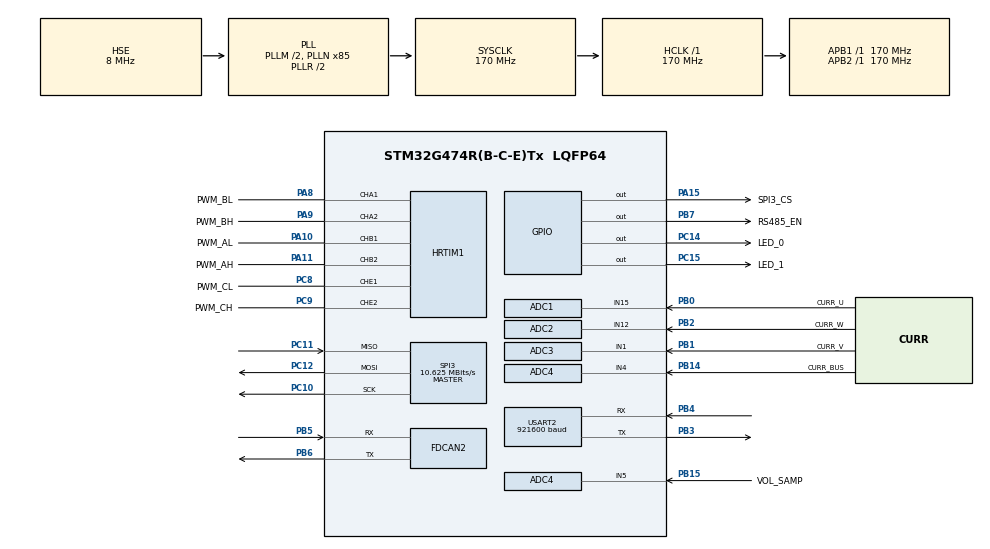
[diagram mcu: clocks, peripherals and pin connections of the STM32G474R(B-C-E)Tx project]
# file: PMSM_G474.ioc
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ADC1.Channel-5\#ChannelRegularConversion=ADC_CHANNEL_15
ADC1.DMAContinuousRequests=ENABLE
ADC1.EOCSelection=ADC_EOC_SEQ_CONV
ADC1.ExternalTrigConv=ADC_EXTERNALTRIG_HRTIM_TRG1
ADC1.NbrOfConversion=1
ADC1.NbrOfConversionFlag=1
ADC1.OffsetNumber-5\#ChannelRegularConversion=ADC_OFFSET_NONE
ADC1.Rank-5\#ChannelRegularConversion=1
ADC1.SamplingTime-5\#ChannelRegularConversion=ADC_SAMPLETIME_47CYCLES_5
ADC1.master=1
ADC2.Channel-4\#ChannelRegularConversion=ADC_CHANNEL_12
ADC2.DMAContinuousRequests=ENABLE
ADC2.ExternalTrigConv=ADC_EXTERNALTRIG_HRTIM_TRG1
ADC2.NbrOfConversionFlag=1
ADC2.OffsetNumber-4\#ChannelRegularConversion=ADC_OFFSET_NONE
ADC2.Rank-4\#ChannelRegularConversion=1
ADC2.SamplingTime-4\#ChannelRegularConversion=ADC_SAMPLETIME_47CYCLES_5
ADC3.Channel-3\#ChannelRegularConversion=ADC_CHANNEL_1
ADC3.DMAContinuousRequests=ENABLE
ADC3.ExternalTrigConv=ADC_EXTERNALTRIG_HRTIM_TRG2
ADC3.NbrOfConversionFlag=1
ADC3.OffsetNumber-3\#ChannelRegularConversion=ADC_OFFSET_NONE
ADC3.Rank-3\#ChannelRegularConversion=1
ADC3.SamplingTime-3\#ChannelRegularConversion=ADC_SAMPLETIME_47CYCLES_5
ADC3.master=1
ADC4.Channel-3\#ChannelRegularConversion=ADC_CHANNEL_5
ADC4.Channel-4\#ChannelRegularConversion=ADC_CHANNEL_4
ADC4.DMAContinuousRequests=ENABLE
ADC4.EOCSelection=ADC_EOC_SEQ_CONV
ADC4.ExternalTrigConv=ADC_EXTERNALTRIG_HRTIM_TRG2
ADC4.NbrOfConversion=2
ADC4.NbrOfConversionFlag=1
ADC4.OffsetNumber-3\#ChannelRegularConversion=ADC_OFFSET_NONE
ADC4.OffsetNumber-4\#ChannelRegularConversion=ADC_OFFSET_NONE
ADC4.Rank-3\#ChannelRegularConversion=1
ADC4.Rank-4\#ChannelRegularConversion=2
ADC4.SamplingTime-3\#ChannelRegularConversion=ADC_SAMPLETIME_47CYCLES_5
ADC4.SamplingTime-4\#ChannelRegularConversion=ADC_SAMPLETIME_47CYCLES_5
Dma.ADC1.2.Direction=DMA_PERIPH_TO_MEMORY
Dma.ADC1.2.EventEnable=DISABLE
Dma.ADC1.2.Instance=DMA1_Channel1
Dma.ADC1.2.MemDataAlignment=DMA_MDATAALIGN_HALFWORD
Dma.ADC1.2.MemInc=DMA_MINC_ENABLE
Dma.ADC1.2.Mode=DMA_CIRCULAR
Dma.ADC1.2.PeriphDataAlignment=DMA_PDATAALIGN_HALFWORD
Dma.ADC1.2.PeriphInc=DMA_PINC_DISABLE
Dma.ADC1.2.Polarity=HAL_DMAMUX_REQ_GEN_RISING
Dma.ADC1.2.Priority=DMA_PRIORITY_LOW
Dma.ADC1.2.RequestNumber=1
Dma.ADC1.2.SignalID=NONE
Dma.ADC1.2.SyncEnable=DISABLE
Dma.ADC1.2.SyncPolarity=HAL_DMAMUX_SYNC_NO_EVENT
Dma.ADC1.2.SyncRequestNumber=1
Dma.ADC1.2.SyncSignalID=NONE
Dma.ADC2.4.Direction=DMA_PERIPH_TO_MEMORY
Dma.ADC2.4.EventEnable=DISABLE
Dma.ADC2.4.Instance=DMA1_Channel5
Dma.ADC2.4.MemDataAlignment=DMA_MDATAALIGN_HALFWORD
Dma.ADC2.4.MemInc=DMA_MINC_ENABLE
Dma.ADC2.4.Mode=DMA_CIRCULAR
Dma.ADC2.4.PeriphDataAlignment=DMA_PDATAALIGN_HALFWORD
Dma.ADC2.4.PeriphInc=DMA_PINC_DISABLE
Dma.ADC2.4.Polarity=HAL_DMAMUX_REQ_GEN_RISING
Dma.ADC2.4.Priority=DMA_PRIORITY_LOW
Dma.ADC2.4.RequestNumber=1
Dma.ADC2.4.SignalID=NONE
Dma.ADC2.4.SyncEnable=DISABLE
Dma.ADC2.4.SyncPolarity=HAL_DMAMUX_SYNC_NO_EVENT
Dma.ADC2.4.SyncRequestNumber=1
Dma.ADC2.4.SyncSignalID=NONE
Dma.ADC3.3.Direction=DMA_PERIPH_TO_MEMORY
Dma.ADC3.3.EventEnable=DISABLE
Dma.ADC3.3.Instance=DMA1_Channel4
Dma.ADC3.3.MemDataAlignment=DMA_MDATAALIGN_HALFWORD
Dma.ADC3.3.MemInc=DMA_MINC_ENABLE
Dma.ADC3.3.Mode=DMA_CIRCULAR
Dma.ADC3.3.PeriphDataAlignment=DMA_PDATAALIGN_HALFWORD
Dma.ADC3.3.PeriphInc=DMA_PINC_DISABLE
Dma.ADC3.3.Polarity=HAL_DMAMUX_REQ_GEN_RISING
Dma.ADC3.3.Priority=DMA_PRIORITY_LOW
Dma.ADC3.3.RequestNumber=1
Dma.ADC3.3.SignalID=NONE
Dma.ADC3.3.SyncEnable=DISABLE
Dma.ADC3.3.SyncPolarity=HAL_DMAMUX_SYNC_NO_EVENT
Dma.ADC3.3.SyncRequestNumber=1
Dma.ADC3.3.SyncSignalID=NONE
Dma.ADC4.5.Direction=DMA_PERIPH_TO_MEMORY
Dma.ADC4.5.EventEnable=DISABLE
Dma.ADC4.5.Instance=DMA1_Channel6
Dma.ADC4.5.MemDataAlignment=DMA_MDATAALIGN_HALFWORD
Dma.ADC4.5.MemInc=DMA_MINC_ENABLE
Dma.ADC4.5.Mode=DMA_CIRCULAR
Dma.ADC4.5.PeriphDataAlignment=DMA_PDATAALIGN_HALFWORD
Dma.ADC4.5.PeriphInc=DMA_PINC_DISABLE
Dma.ADC4.5.Polarity=HAL_DMAMUX_REQ_GEN_RISING
Dma.ADC4.5.Priority=DMA_PRIORITY_LOW
Dma.ADC4.5.RequestNumber=1
Dma.ADC4.5.SignalID=NONE
Dma.ADC4.5.SyncEnable=DISABLE
Dma.ADC4.5.SyncPolarity=HAL_DMAMUX_SYNC_NO_EVENT
Dma.ADC4.5.SyncRequestNumber=1
Dma.ADC4.5.SyncSignalID=NONE
Dma.Request0=USART2_TX
Dma.Request1=SPI3_RX
Dma.Request2=ADC1
Dma.Request3=ADC3
Dma.Request4=ADC2
Dma.Request5=ADC4
Dma.Request6=SPI3_TX
Dma.SPI3_RX.1.Direction=DMA_PERIPH_TO_MEMORY
Dma.SPI3_RX.1.EventEnable=DISABLE
Dma.SPI3_RX.1.Instance=DMA1_Channel3
Dma.SPI3_RX.1.MemDataAlignment=DMA_MDATAALIGN_BYTE
Dma.SPI3_RX.1.MemInc=DMA_MINC_ENABLE
Dma.SPI3_RX.1.Mode=DMA_NORMAL
Dma.SPI3_RX.1.PeriphDataAlignment=DMA_PDATAALIGN_BYTE
Dma.SPI3_RX.1.PeriphInc=DMA_PINC_DISABLE
Dma.SPI3_RX.1.Polarity=HAL_DMAMUX_REQ_GEN_RISING
Dma.SPI3_RX.1.Priority=DMA_PRIORITY_LOW
Dma.SPI3_RX.1.RequestNumber=1
Dma.SPI3_RX.1.SignalID=NONE
Dma.SPI3_RX.1.SyncEnable=DISABLE
Dma.SPI3_RX.1.SyncPolarity=HAL_DMAMUX_SYNC_NO_EVENT
Dma.SPI3_RX.1.SyncRequestNumber=1
Dma.SPI3_RX.1.SyncSignalID=NONE
Dma.SPI3_TX.6.Direction=DMA_MEMORY_TO_PERIPH
Dma.SPI3_TX.6.EventEnable=DISABLE
Dma.SPI3_TX.6.Instance=DMA1_Channel7
Dma.SPI3_TX.6.MemDataAlignment=DMA_MDATAALIGN_BYTE
Dma.SPI3_TX.6.MemInc=DMA_MINC_ENABLE
Dma.SPI3_TX.6.Mode=DMA_NORMAL
Dma.SPI3_TX.6.PeriphDataAlignment=DMA_PDATAALIGN_BYTE
Dma.SPI3_TX.6.PeriphInc=DMA_PINC_DISABLE
Dma.SPI3_TX.6.Polarity=HAL_DMAMUX_REQ_GEN_RISING
Dma.SPI3_TX.6.Priority=DMA_PRIORITY_LOW
Dma.SPI3_TX.6.RequestNumber=1
Dma.SPI3_TX.6.SignalID=NONE
Dma.SPI3_TX.6.SyncEnable=DISABLE
Dma.SPI3_TX.6.SyncPolarity=HAL_DMAMUX_SYNC_NO_EVENT
Dma.SPI3_TX.6.SyncRequestNumber=1
Dma.SPI3_TX.6.SyncSignalID=NONE
Dma.USART2_TX.0.Direction=DMA_MEMORY_TO_PERIPH
Dma.USART2_TX.0.EventEnable=DISABLE
Dma.USART2_TX.0.Instance=DMA1_Channel2
Dma.USART2_TX.0.MemDataAlignment=DMA_MDATAALIGN_BYTE
Dma.USART2_TX.0.MemInc=DMA_MINC_ENABLE
Dma.USART2_TX.0.Mode=DMA_NORMAL
Dma.USART2_TX.0.PeriphDataAlignment=DMA_PDATAALIGN_BYTE
Dma.USART2_TX.0.PeriphInc=DMA_PINC_DISABLE
Dma.USART2_TX.0.Polarity=HAL_DMAMUX_REQ_GEN_RISING
Dma.USART2_TX.0.Priority=DMA_PRIORITY_LOW
Dma.USART2_TX.0.RequestNumber=1
Dma.USART2_TX.0.SignalID=NONE
Dma.USART2_TX.0.SyncEnable=DISABLE
Dma.USART2_TX.0.SyncPolarity=HAL_DMAMUX_SYNC_NO_EVENT
Dma.USART2_TX.0.SyncRequestNumber=1
Dma.USART2_TX.0.SyncSignalID=NONE
FDCAN2.CalculateBaudRateNominal=999999
FDCAN2.CalculateTimeBitNominal=1000
FDCAN2.CalculateTimeQuantumNominal=58.82352941176471
FDCAN2.DataPrescaler=17
FDCAN2.DataSyncJumpWidth=9
FDCAN2.DataTimeSeg1=5
FDCAN2.DataTimeSeg2=4
FDCAN2.NominalPrescaler=10
FDCAN2.NominalSyncJumpWidth=9
FDCAN2.NominalTimeSeg1=8
FDCAN2.NominalTimeSeg2=8
FDCAN2.StdFiltersNbr=1
HRTIM1.ADCTrigger1_Source1=HRTIM_ADCTRIGGEREVENT13_MASTER_CMP1
HRTIM1.ADCTrigger2_Source1=HRTIM_ADCTRIGGEREVENT24_MASTER_CMP1
HRTIM1.ADCTrigger4_Source1=HRTIM_ADCTRIGGEREVENT24_MASTER_PERIOD
HRTIM1.ADCTrigger_Id1=HRTIM_ADCTRIGGER_1
HRTIM1.ADCTrigger_Id2=HRTIM_ADCTRIGGER_2
HRTIM1.ADCTrigger_Id4=HRTIM_ADCTRIGGER_4
HRTIM1.CompareUnit1-MasterTimer=HRTIM_COMPAREUNIT_1
HRTIM1.CompareUnit1-Output_TA1TA2=HRTIM_COMPAREUNIT_1
HRTIM1.CompareUnit1-Output_TB1TB2=HRTIM_COMPAREUNIT_1
HRTIM1.CompareUnit1-Output_TE1TE2=HRTIM_COMPAREUNIT_1
HRTIM1.CompareValue1-MasterTimer=ADC_TRIG
HRTIM1.CompareValue1-Output_TA1TA2=0xFFFB
HRTIM1.DeadTimeInsertion-Output_TA1TA2=HRTIM_TIMDEADTIMEINSERTION_ENABLED
HRTIM1.DeadTimeInsertion-Output_TB1TB2=HRTIM_TIMDEADTIMEINSERTION_ENABLED
HRTIM1.DeadTimeInsertion-Output_TE1TE2=HRTIM_TIMDEADTIMEINSERTION_ENABLED
HRTIM1.Deadtimeconfig-Output_TB1TB2=HRTIM_TIMERINDEX_TIMER_B
HRTIM1.FallingValue-Output_TA1TA2=0x032
HRTIM1.FallingValue-Output_TB1TB2=0x032
HRTIM1.FallingValue-Output_TE1TE2=0x032
HRTIM1.GreaterCMP1_TA=HRTIM_TIMERGTCMP1_GREATER
HRTIM1.GreaterCMP1_TB=HRTIM_TIMERGTCMP1_GREATER
HRTIM1.GreaterCMP1_TE=HRTIM_TIMERGTCMP1_GREATER
HRTIM1.InterleavedMode-MasterTimer=HRTIM_INTERLEAVED_MODE_DISABLED
HRTIM1.InterruptRequests1_Master=HRTIM_MASTER_IT_MREP
HRTIM1.InterruptRequests2_Master=HRTIM_MASTER_IT_MUPD
HRTIM1.ModeTimeBase-Output_TA1TA2=HRTIM_MODE_CONTINUOUS
HRTIM1.ModeTimeBase-Output_TB1TB2=HRTIM_MODE_CONTINUOUS
HRTIM1.NumberADCTriggerSource1=1
HRTIM1.NumberADCTriggerSource2=1
HRTIM1.NumberADCTriggerSource4=1
HRTIM1.NumberInterruptRequests-Output_TE1TE2=0
HRTIM1.NumberInterruptRequests_Master-MasterTimer=2
HRTIM1.NumberResetSource1-Output_TA1TA2=0
HRTIM1.NumberResetSource1-Output_TB1TB2=0
HRTIM1.NumberResetSource1-Output_TE1TE2=0
HRTIM1.NumberResetTrigger-Output_TA1TA2=0
HRTIM1.NumberResetTrigger-Output_TB1TB2=0
HRTIM1.NumberResetTrigger-Output_TE1TE2=0
HRTIM1.NumberSetSource1-Output_TA1TA2=1
HRTIM1.NumberSetSource1-Output_TB1TB2=1
HRTIM1.NumberSetSource1-Output_TE1TE2=1
HRTIM1.NumberUpdateTrigger-Output_TA1TA2=1
HRTIM1.NumberUpdateTrigger-Output_TB1TB2=1
HRTIM1.NumberUpdateTrigger-Output_TE1TE2=1
HRTIM1.Periode_MASTER=MASTER_ARR
HRTIM1.Periode_TA=HRTIMR_ARR
HRTIM1.Periode_TB=HRTIMR_ARR
HRTIM1.Periode_TE=HRTIMR_ARR
HRTIM1.PreloadEnable-MasterTimer=HRTIM_PRELOAD_ENABLED
HRTIM1.PreloadEnable-Output_TA1TA2=HRTIM_PRELOAD_ENABLED
HRTIM1.PreloadEnable-Output_TB1TB2=HRTIM_PRELOAD_ENABLED
HRTIM1.PreloadEnable-Output_TE1TE2=HRTIM_PRELOAD_ENABLED
HRTIM1.PrescalerDead-Output_TA1TA2=HRTIM_TIMDEADTIME_PRESCALERRATIO_DIV1
HRTIM1.PrescalerDead-Output_TB1TB2=HRTIM_TIMDEADTIME_PRESCALERRATIO_DIV1
HRTIM1.PrescalerDead-Output_TE1TE2=HRTIM_TIMDEADTIME_PRESCALERRATIO_DIV1
HRTIM1.PrescalerRatio_MASTER=HRTIM_PRESCALERRATIO_MUL4
HRTIM1.PrescalerRatio_TA=HRTIM_PRESCALERRATIO_MUL4
HRTIM1.PrescalerRatio_TB=HRTIM_PRESCALERRATIO_MUL4
HRTIM1.PrescalerRatio_TE=HRTIM_PRESCALERRATIO_MUL4
HRTIM1.PushPull-Output_TA1TA2=HRTIM_TIMPUSHPULLMODE_DISABLED
HRTIM1.PushPull-Output_TB1TB2=HRTIM_TIMPUSHPULLMODE_DISABLED
HRTIM1.PushPull-Output_TE1TE2=HRTIM_TIMPUSHPULLMODE_DISABLED
HRTIM1.RepetitionUpdate-MasterTimer=HRTIM_UPDATEONREPETITION_ENABLED
HRTIM1.RepetitionUpdate-Output_TA1TA2=HRTIM_UPDATEONREPETITION_ENABLED
HRTIM1.RepetitionUpdate-Output_TB1TB2=HRTIM_UPDATEONREPETITION_ENABLED
HRTIM1.RepetitionUpdate-Output_TE1TE2=HRTIM_UPDATEONREPETITION_ENABLED
HRTIM1.RisingValue-Output_TA1TA2=0x032
HRTIM1.RisingValue-Output_TB1TB2=0x032
HRTIM1.RisingValue-Output_TE1TE2=0x032
HRTIM1.SetOutput1_Source1-Output_TA1TA2=HRTIM_OUTPUTSET_TIMCMP1
HRTIM1.SetOutput1_Source1-Output_TB1TB2=HRTIM_OUTPUTSET_TIMCMP1
HRTIM1.SetOutput1_Source1-Output_TE1TE2=HRTIM_OUTPUTSET_TIMCMP1
HRTIM1.UpDownMode-Output_TA1TA2=HRTIM_TIMERUPDOWNMODE_UPDOWN
HRTIM1.UpDownMode-Output_TB1TB2=HRTIM_TIMERUPDOWNMODE_UPDOWN
HRTIM1.UpDownMode-Output_TE1TE2=HRTIM_TIMERUPDOWNMODE_UPDOWN
HRTIM1.UpdateTrigger1-Output_TA1TA2=HRTIM_TIMUPDATETRIGGER_MASTER
HRTIM1.UpdateTrigger1-Output_TB1TB2=HRTIM_TIMUPDATETRIGGER_MASTER
HRTIM1.UpdateTrigger1-Output_TE1TE2=HRTIM_TIMUPDATETRIGGER_MASTER
HRTIM1.postscaler4=0x63
Mcu.Family=STM32G4
Mcu.Name=STM32G474R(B-C-E)Tx
Mcu.Package=LQFP64
Mcu.UserConstants=PWM_FREQ,20000;HRTIMR_ARR,MASTER_ARR/2;MASTER_ARR,680000000/PWM_FREQ;ADC_TRIG,MASTER_ARR/2
NVIC.DMA1_Channel1_IRQn=true\:3\:0\:true\:false\:true\:true\:true\:true
NVIC.DMA1_Channel2_IRQn=true\:6\:0\:true\:false\:true\:true\:true\:true
NVIC.DMA1_Channel3_IRQn=true\:6\:0\:true\:false\:true\:true\:true\:true
NVIC.DMA1_Channel4_IRQn=true\:3\:0\:true\:false\:true\:true\:true\:true
NVIC.DMA1_Channel5_IRQn=true\:3\:0\:true\:false\:true\:true\:true\:true
NVIC.DMA1_Channel6_IRQn=true\:6\:0\:true\:false\:true\:true\:true\:true
NVIC.DMA1_Channel7_IRQn=true\:6\:0\:true\:false\:true\:true\:true\:true
NVIC.FDCAN2_IT0_IRQn=true\:7\:0\:true\:false\:true\:true\:true\:true
NVIC.HRTIM1_Master_IRQn=true\:2\:0\:true\:false\:true\:true\:true\:true
NVIC.PriorityGroup=NVIC_PRIORITYGROUP_4
NVIC.SPI3_IRQn=true\:5\:0\:true\:false\:true\:true\:true\:true
NVIC.TIM6_DAC_IRQn=true\:4\:0\:true\:false\:true\:true\:true\:true
NVIC.USART2_IRQn=true\:7\:0\:true\:false\:true\:true\:true\:true
PA10.GPIO_Label=PWM_AL
PA10.Mode=Output_TB1TB2
PA10.Signal=HRTIM1_CHB1
PA11.GPIO_Label=PWM_AH
PA11.Mode=Output_TB1TB2
PA11.Signal=HRTIM1_CHB2
PA13.Mode=Serial_Wire
PA13.Signal=SYS_JTMS-SWDIO
PA14.Mode=Serial_Wire
PA14.Signal=SYS_JTCK-SWCLK
PA15.GPIO_Label=SPI3_CS
PA15.GPIO_PuPd=GPIO_PULLUP
PA15.PinState=GPIO_PIN_SET
PA15.Signal=GPIO_Output
PA8.GPIO_Label=PWM_BL
PA8.Mode=Output_TA1TA2
PA8.Signal=HRTIM1_CHA1
PA9.GPIO_Label=PWM_BH
PA9.Mode=Output_TA1TA2
PA9.Signal=HRTIM1_CHA2
PB0.GPIO_Label=CURR_U
PB0.Mode=IN15-Single-Ended
PB0.Signal=ADC1_IN15
PB1.GPIO_Label=CURR_V
PB1.Mode=IN1-Single-Ended
PB1.Signal=ADC3_IN1
PB14.GPIO_Label=CURR_BUS
PB14.Mode=IN4-Single-Ended
PB14.Signal=ADC4_IN4
PB15.GPIO_Label=VOL_SAMP
PB15.Mode=IN5-Single-Ended
PB15.Signal=ADC4_IN5
PB2.GPIO_Label=CURR_W
PB2.Mode=IN12-Single-Ended
PB2.Signal=ADC2_IN12
PB3.Mode=Asynchronous
PB3.Signal=USART2_TX
PB4.Mode=Asynchronous
PB4.Signal=USART2_RX
PB5.Mode=FDCAN_Activate
PB5.Signal=FDCAN2_RX
PB6.Mode=FDCAN_Activate
PB6.Signal=FDCAN2_TX
PB7.GPIO_Label=RS485_EN
PB7.GPIO_PuPd=GPIO_PULLUP
PB7.PinState=GPIO_PIN_SET
PB7.Signal=GPIO_Output
PB8-BOOT0.GPIO_Label=RS485_RX
PB8-BOOT0.Signal=USART3_RX
PB9.GPIO_Label=RS485_TX
PB9.Signal=USART3_TX
PC10.GPIO_PuPd=GPIO_PULLUP
PC10.Mode=Full_Duplex_Master
PC10.Signal=SPI3_SCK
PC11.GPIO_PuPd=GPIO_NOPULL
PC11.Mode=Full_Duplex_Master
PC11.Signal=SPI3_MISO
PC12.GPIO_PuPd=GPIO_NOPULL
PC12.Mode=Full_Duplex_Master
PC12.Signal=SPI3_MOSI
PC14-OSC32_IN.GPIO_Label=LED_0
PC14-OSC32_IN.GPIO_PuPd=GPIO_PULLUP
PC14-OSC32_IN.PinState=GPIO_PIN_SET
PC14-OSC32_IN.Signal=GPIO_Output
PC15-OSC32_OUT.GPIO_Label=LED_1
PC15-OSC32_OUT.GPIO_PuPd=GPIO_PULLUP
PC15-OSC32_OUT.PinState=GPIO_PIN_SET
PC15-OSC32_OUT.Signal=GPIO_Output
PC8.GPIO_Label=PWM_CL
PC8.Mode=Output_TE1TE2
PC8.Signal=HRTIM1_CHE1
PC9.GPIO_Label=PWM_CH
PC9.Mode=Output_TE1TE2
PC9.Signal=HRTIM1_CHE2
PF0-OSC_IN.Mode=HSE-External-Oscillator
PF0-OSC_IN.Signal=RCC_OSC_IN
PF1-OSC_OUT.Mode=HSE-External-Oscillator
PF1-OSC_OUT.Signal=RCC_OSC_OUT
ProjectManager.HeapSize=0x200
ProjectManager.StackSize=0x400
ProjectManager.TargetToolchain=MDK-ARM V5.32
RCC.ADC12Freq_Value=170000000
RCC.ADC345Freq_Value=170000000
RCC.AHBFreq_Value=170000000
RCC.APB1Freq_Value=170000000
RCC.APB1TimFreq_Value=170000000
RCC.APB2Freq_Value=170000000
RCC.APB2TimFreq_Value=170000000
RCC.CortexFreq_Value=170000000
RCC.EXTERNAL_CLOCK_VALUE=12288000
RCC.HCLKFreq_Value=170000000
RCC.HSE_VALUE=8000000
RCC.HSI48_VALUE=48000000
RCC.HSI_VALUE=16000000
RCC.LSE_VALUE=32768
RCC.PLLM=RCC_PLLM_DIV2
RCC.PLLN=85
RCC.PLLSourceVirtual=RCC_PLLSOURCE_HSE
RCC.SYSCLKFreq_VALUE=170000000
RCC.SYSCLKSource=RCC_SYSCLKSOURCE_PLLCLK
RCC.USBFreq_Value=170000000
RCC.VCOOutputFreq_Value=340000000
SPI3.BaudRatePrescaler=SPI_BAUDRATEPRESCALER_16
SPI3.CLKPhase=SPI_PHASE_2EDGE
SPI3.CLKPolarity=SPI_POLARITY_HIGH
SPI3.CalculateBaudRate=10.625 MBits/s
SPI3.DataSize=SPI_DATASIZE_8BIT
SPI3.Direction=SPI_DIRECTION_2LINES
SPI3.Mode=SPI_MODE_MASTER
SPI3.VirtualType=VM_MASTER
STMicroelectronics.X-CUBE-ALGOBUILD.1.4.0.LibraryCcDSPOoLibraryJjDSPOoLibrary=true
TIM6.PeriodNoDither=499
TIM6.Prescaler=169
USART2.BaudRate=921600
USART2.VirtualMode-Asynchronous=VM_ASYNC
VP_HRTIM1_VS_hrtimMasterTimerNoOutput.Mode=MasterTimer
VP_STMicroelectronics.X-CUBE-ALGOBUILD_VS_DSPOoLibraryJjLibrary_1.4.0_1.4.0.Mode=DSPOoLibraryJjLibrary
VP_SYS_VS_DBSignals.Mode=DisableDeadBatterySignals
VP_TIM6_VS_ClockSourceINT.Mode=Enable_Timer
board=custom

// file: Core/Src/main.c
/* USER CODE BEGIN Header */
/**
  ******************************************************************************
  * @file           : main.c
  * @brief          : Main program body
  ******************************************************************************
  * @attention
  *
  * Copyright (c) 2026 STMicroelectronics.
  * All rights reserved.
  *
  * This software is licensed under terms that can be found in the LICENSE file
  * in the root directory of this software component.
  * If no LICENSE file comes with this software, it is provided AS-IS.
  *
  ******************************************************************************
  */
/* USER CODE END Header */
#include "main.h"
#include "adc.h"
#include "dma.h"
#include "fdcan.h"
#include "hrtim.h"
#include "spi.h"
#include "tim.h"
#include "usart.h"
#include "gpio.h"

/* USER CODE BEGIN Includes */
#include "arm_math.h"
#include "MY_Init.h"
#include "VOFA.h"
#include <stdint.h>
/* USER CODE END Includes */

/* USER CODE BEGIN PV */

uint8_t Test = 0;

/* USER CODE END PV */

void SystemClock_Config(void);

int main(void)
{

  /* MCU Configuration--------------------------------------------------------*/

  /* Reset of all peripherals, Initializes the Flash interface and the Systick. */
  HAL_Init();

  /* Configure the system clock */
  SystemClock_Config();

  /* Initialize all configured peripherals */
  MX_GPIO_Init();
  MX_DMA_Init();
  MX_ADC1_Init();
  MX_ADC2_Init();
  MX_FDCAN2_Init();
  MX_HRTIM1_Init();
  MX_SPI3_Init();
  MX_USART2_UART_Init();
  MX_ADC3_Init();
  MX_ADC4_Init();
  MX_TIM6_Init();
  /* USER CODE BEGIN 2 */
  My_Init();
  UART_Receive();
  /* USER CODE END 2 */

  /* Infinite loop */
  while (1)
  {

    /* USER CODE BEGIN 3 */
    HAL_GPIO_TogglePin(LED_0_GPIO_Port, LED_0_Pin);
    HAL_Delay(200);

  }
  /* USER CODE END 3 */
}

void SystemClock_Config(void)
{
  RCC_OscInitTypeDef RCC_OscInitStruct = {0};
  RCC_ClkInitTypeDef RCC_ClkInitStruct = {0};

  /** Configure the main internal regulator output voltage
  */
  HAL_PWREx_ControlVoltageScaling(PWR_REGULATOR_VOLTAGE_SCALE1_BOOST);

  /** Initializes the RCC Oscillators according to the specified parameters
  * in the RCC_OscInitTypeDef structure.
  */
  RCC_OscInitStruct.OscillatorType = RCC_OSCILLATORTYPE_HSE;
  RCC_OscInitStruct.HSEState = RCC_HSE_ON;
  RCC_OscInitStruct.PLL.PLLState = RCC_PLL_ON;
  RCC_OscInitStruct.PLL.PLLSource = RCC_PLLSOURCE_HSE;
  RCC_OscInitStruct.PLL.PLLM = RCC_PLLM_DIV2;
  RCC_OscInitStruct.PLL.PLLN = 85;
  RCC_OscInitStruct.PLL.PLLP = RCC_PLLP_DIV2;
  RCC_OscInitStruct.PLL.PLLQ = RCC_PLLQ_DIV2;
  RCC_OscInitStruct.PLL.PLLR = RCC_PLLR_DIV2;
  if (HAL_RCC_OscConfig(&RCC_OscInitStruct) != HAL_OK)
  {
    Error_Handler();
  }

  /** Initializes the CPU, AHB and APB buses clocks
  */
  RCC_ClkInitStruct.ClockType = RCC_CLOCKTYPE_HCLK|RCC_CLOCKTYPE_SYSCLK
                              |RCC_CLOCKTYPE_PCLK1|RCC_CLOCKTYPE_PCLK2;
  RCC_ClkInitStruct.SYSCLKSource = RCC_SYSCLKSOURCE_PLLCLK;
  RCC_ClkInitStruct.AHBCLKDivider = RCC_SYSCLK_DIV1;
  RCC_ClkInitStruct.APB1CLKDivider = RCC_HCLK_DIV1;
  RCC_ClkInitStruct.APB2CLKDivider = RCC_HCLK_DIV1;

  if (HAL_RCC_ClockConfig(&RCC_ClkInitStruct, FLASH_LATENCY_4) != HAL_OK)
  {
    Error_Handler();
  }
}

void Error_Handler(void)
{
  __disable_irq();
  while (1)
  {
  }
}
